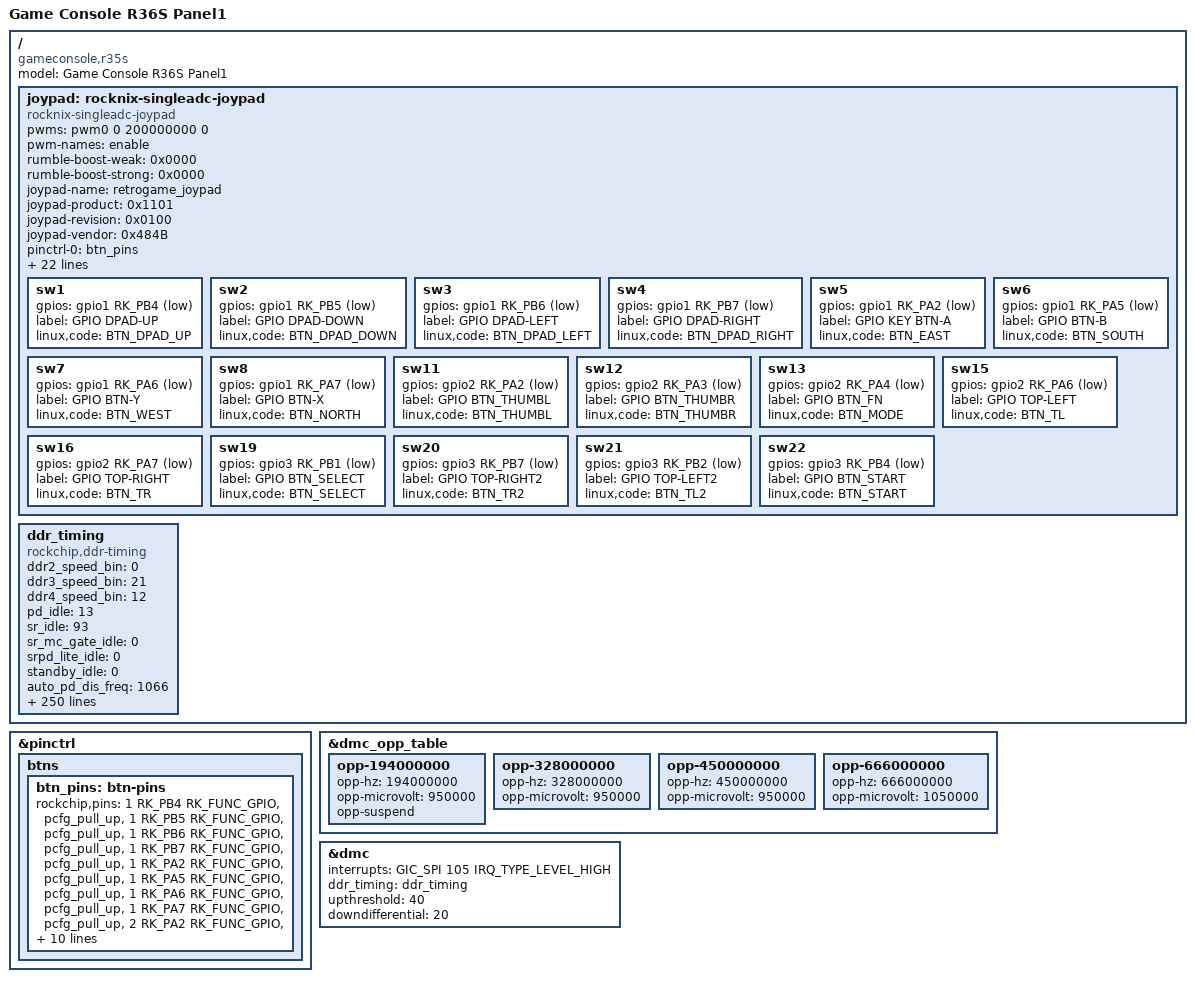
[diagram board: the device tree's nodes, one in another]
// SPDX-License-Identifier: (GPL-2.0+ OR MIT)
/*
* # Copyright (C) 2022-24 JELOS (https://github.com/JustEnoughLinuxOS)
*/

/dts-v1/;
#include "rk3326-gameconsole-r3xs.dtsi"
#include "rk3326-device-group-r36.dtsi"

/ {
	model = "Game Console R36S Panel1";
	compatible = "gameconsole,r35s", "gameconsole,r36s", "rockchip,rk3326";
	
	joypad: rocknix-singleadc-joypad {
		compatible = "rocknix-singleadc-joypad";
		pwms = <&pwm0 0 200000000 0>;
		pwm-names = "enable";
		rumble-boost-weak = <0x0000>;
		rumble-boost-strong = <0x0000>;
		
		joypad-name = "retrogame_joypad";
		joypad-product = <0x1101>;
		joypad-revision = <0x0100>;
		joypad-vendor = <0x484B>;
		
		status = "okay";
		
		/* gpio pincontrol setup */
		pinctrl-names = "default";
		pinctrl-0 = <&btn_pins>;
		pinctrl-1 = <&pwm0_pin>;
		
		/* Analog mux define */
		io-channel-names = "amux_adc";
		io-channels = <&saradc 1>;
		
		/* adc mux channel count */
		amux-count = <4>;
		/* non-default wiring */
		amux-channel-mapping = <0 1 2 3>;
		/* adc mux select(a,b) gpio */
		amux-a-gpios = <&gpio3 RK_PB3 GPIO_ACTIVE_LOW>;
		amux-b-gpios = <&gpio3 RK_PB0 GPIO_ACTIVE_LOW>;
		/* adc mux enable gpio */
		amux-en-gpios = <&gpio3 RK_PB5 GPIO_ACTIVE_LOW>;
		
		/* adc calculate scale */
		button-adc-scale = <2>;
		
		/* adc deadzone range  */
		button-adc-deadzone = <64>;
		
		/*
		specifies fuzz value that is used to filter noise from
		the event stream.
		*/
		button-adc-fuzz = <32>;
		button-adc-flat = <32>;
		
		/*
		Analog Stick data tuning value(precent)
		p = positive direction, n = negative direction
		report value = (real_adc_data * tuning_value) / 100
		*/
		abs_x-p-tuning = <200>;
		abs_x-n-tuning = <200>;
		
		abs_y-p-tuning = <200>;
		abs_y-n-tuning = <200>;
		
		abs_rx-p-tuning = <200>;
		abs_rx-n-tuning = <200>;
		
		abs_ry-p-tuning = <200>;
		abs_ry-n-tuning = <200>;
		
		/* poll device interval (ms), adc read interval */
		poll-interval = <10>;
		
		/* required for RG36S */
		invert-absx;
		invert-absy;
		
		/* gpio button auto repeat set value : default disable */
		/*
		autorepeat;
		*/
		
		/*
		joypad driver is poll-device driver.
		poll-device is does not support wakeup-source.
		*/
		sw1 {
			gpios = <&gpio1 RK_PB4 GPIO_ACTIVE_LOW>;
			label = "GPIO DPAD-UP";
			linux,code = <BTN_DPAD_UP>;// 0x220
		};
		sw2 {
			gpios = <&gpio1 RK_PB5 GPIO_ACTIVE_LOW>;
			label = "GPIO DPAD-DOWN";
			linux,code = <BTN_DPAD_DOWN>;// 0x221
		};
		sw3 {
			gpios = <&gpio1 RK_PB6 GPIO_ACTIVE_LOW>;
			label = "GPIO DPAD-LEFT";
			linux,code = <BTN_DPAD_LEFT>;// 0x222
		};
		sw4 {
			gpios = <&gpio1 RK_PB7 GPIO_ACTIVE_LOW>;
			label = "GPIO DPAD-RIGHT";
			linux,code = <BTN_DPAD_RIGHT>;// 0x223
		};
		sw5 {
			gpios = <&gpio1 RK_PA2 GPIO_ACTIVE_LOW>;
			label = "GPIO KEY BTN-A";
			linux,code = <BTN_EAST>;// 0x131
		};
		sw6 {
			gpios = <&gpio1 RK_PA5 GPIO_ACTIVE_LOW>;
			label = "GPIO BTN-B";
			linux,code = <BTN_SOUTH>;// 0x130
		};
		sw7 {
			gpios = <&gpio1 RK_PA6 GPIO_ACTIVE_LOW>;
			label = "GPIO BTN-Y";
			linux,code = <BTN_WEST>;// 0x134
		};
		sw8 {
			gpios = <&gpio1 RK_PA7 GPIO_ACTIVE_LOW>;
			label = "GPIO BTN-X";
			linux,code = <BTN_NORTH>;// 0x133
		};
		sw11 {
			gpios = <&gpio2 RK_PA2 GPIO_ACTIVE_LOW>;
			label = "GPIO BTN_THUMBL";
			linux,code = <BTN_THUMBL>;// 0x2c2
		};
		sw12 {
			gpios = <&gpio2 RK_PA3 GPIO_ACTIVE_LOW>;
			label = "GPIO BTN_THUMBR";
			linux,code = <BTN_THUMBR>;// 0x2c3
		};
		sw13 {
			gpios = <&gpio2 RK_PA4 GPIO_ACTIVE_LOW>;
			label = "GPIO BTN_FN";
			linux,code = <BTN_MODE>;// 0x2c4
		};
		sw15 {
			gpios = <&gpio2 RK_PA6 GPIO_ACTIVE_LOW>;
			label = "GPIO TOP-LEFT";
			linux,code = <BTN_TL>;// 0x02
		};
		sw16 {
			gpios = <&gpio2 RK_PA7 GPIO_ACTIVE_LOW>;
			label = "GPIO TOP-RIGHT";
			linux,code = <BTN_TR>;// 0x05
		};
		sw19 {
			gpios = <&gpio3 RK_PB1 GPIO_ACTIVE_LOW>;
			label = "GPIO BTN_SELECT";
			linux,code = <BTN_SELECT>;
		};
		sw20 {
			gpios = <&gpio3 RK_PB7 GPIO_ACTIVE_LOW>;
			label = "GPIO TOP-RIGHT2";
			linux,code = <BTN_TR2>;
		};
		sw21 {
			gpios = <&gpio3 RK_PB2 GPIO_ACTIVE_LOW>;
			label = "GPIO TOP-LEFT2";
			linux,code = <BTN_TL2>;
		};
		sw22 {
			gpios = <&gpio3 RK_PB4 GPIO_ACTIVE_LOW>;
			label = "GPIO BTN_START";
			linux,code = <BTN_START>;
		};
	};
	ddr_timing: ddr_timing {
		compatible = "rockchip,ddr-timing";
		ddr2_speed_bin = <0>;
		ddr3_speed_bin = <21>;
		ddr4_speed_bin = <12>;
		pd_idle = <13>;
		sr_idle = <93>;
		sr_mc_gate_idle = <0>;
		srpd_lite_idle = <0>;
		standby_idle = <0>;
		auto_pd_dis_freq = <1066>;
		auto_sr_dis_freq = <800>;
		ddr2_dll_dis_freq = <300>;
		ddr3_dll_dis_freq = <300>;
		ddr4_dll_dis_freq = <625>;
		phy_dll_dis_freq = <400>;
		ddr2_odt_dis_freq = <100>;
		phy_ddr2_odt_dis_freq = <100>;
		ddr2_drv = <1>;
		ddr2_odt = <150>;
		phy_ddr2_ca_drv = <21>;
		phy_ddr2_ck_drv = <18>;
		phy_ddr2_dq_drv = <21>;
		phy_ddr2_odt = <2>;
		ddr3_odt_dis_freq = <400>;
		phy_ddr3_odt_dis_freq = <400>;
		ddr3_drv = <40>;
		ddr3_odt = <120>;
		phy_ddr3_ca_drv = <21>;
		phy_ddr3_ck_drv = <18>;
		phy_ddr3_dq_drv = <21>;
		phy_ddr3_odt = <2>;
		phy_lpddr2_odt_dis_freq = <666>;
		lpddr2_drv = <40>;
		phy_lpddr2_ca_drv = <22>;
		phy_lpddr2_ck_drv = <19>;
		phy_lpddr2_dq_drv = <22>;
		phy_lpddr2_odt = <0>;
		lpddr3_odt_dis_freq = <400>;
		phy_lpddr3_odt_dis_freq = <400>;
		lpddr3_drv = <40>;
		lpddr3_odt = <240>;
		phy_lpddr3_ca_drv = <22>;
		phy_lpddr3_ck_drv = <19>;
		phy_lpddr3_dq_drv = <22>;
		phy_lpddr3_odt = <2>;
		lpddr4_odt_dis_freq = <800>;
		phy_lpddr4_odt_dis_freq = <800>;
		lpddr4_drv = <60>;
		lpddr4_dq_odt = <40>;
		lpddr4_ca_odt = <40>;
		phy_lpddr4_ca_drv = <20>;
		phy_lpddr4_ck_cs_drv = <6>;
		phy_lpddr4_dq_drv = <6>;
		phy_lpddr4_odt = <16>;
		ddr4_odt_dis_freq = <625>;
		phy_ddr4_odt_dis_freq = <625>;
		ddr4_drv = <34>;
		ddr4_odt = <240>;
		phy_ddr4_ca_drv = <22>;
		phy_ddr4_ck_drv = <19>;
		phy_ddr4_dq_drv = <22>;
		phy_ddr4_odt = <2>;
		ddr3a1_ddr4a9_de-skew = <6>;
		ddr3a0_ddr4a10_de-skew = <7>;
		ddr3a3_ddr4a6_de-skew = <7>;
		ddr3a2_ddr4a4_de-skew = <7>;
		ddr3a5_ddr4a8_de-skew = <7>;
		ddr3a4_ddr4a5_de-skew = <7>;
		ddr3a7_ddr4a11_de-skew = <7>;
		ddr3a6_ddr4a7_de-skew = <6>;
		ddr3a9_ddr4a0_de-skew = <7>;
		ddr3a8_ddr4a13_de-skew = <7>;
		ddr3a11_ddr4a3_de-skew = <7>;
		ddr3a10_ddr4cs0_de-skew = <7>;
		ddr3a13_ddr4a2_de-skew = <7>;
		ddr3a12_ddr4ba1_de-skew = <7>;
		ddr3a15_ddr4odt0_de-skew = <7>;
		ddr3a14_ddr4a1_de-skew = <7>;
		ddr3ba1_ddr4a15_de-skew = <7>;
		ddr3ba0_ddr4bg0_de-skew = <7>;
		ddr3ras_ddr4cke_de-skew = <7>;
		ddr3ba2_ddr4ba0_de-skew = <7>;
		ddr3we_ddr4bg1_de-skew = <7>;
		ddr3cas_ddr4a12_de-skew = <7>;
		ddr3ckn_ddr4ckn_de-skew = <7>;
		ddr3ckp_ddr4ckp_de-skew = <7>;
		ddr3cke_ddr4a16_de-skew = <7>;
		ddr3odt0_ddr4a14_de-skew = <7>;
		ddr3cs0_ddr4act_de-skew = <6>;
		ddr3reset_ddr4reset_de-skew = <7>;
		ddr3cs1_ddr4cs1_de-skew = <6>;
		ddr3odt1_ddr4odt1_de-skew = <7>;
		cs0_dm0_rx_de-skew = <7>;
		cs0_dm0_tx_de-skew = <7>;
		cs0_dq0_rx_de-skew = <8>;
		cs0_dq0_tx_de-skew = <8>;
		cs0_dq1_rx_de-skew = <9>;
		cs0_dq1_tx_de-skew = <8>;
		cs0_dq2_rx_de-skew = <8>;
		cs0_dq2_tx_de-skew = <8>;
		cs0_dq3_rx_de-skew = <8>;
		cs0_dq3_tx_de-skew = <8>;
		cs0_dq4_rx_de-skew = <9>;
		cs0_dq4_tx_de-skew = <8>;
		cs0_dq5_rx_de-skew = <9>;
		cs0_dq5_tx_de-skew = <8>;
		cs0_dq6_rx_de-skew = <9>;
		cs0_dq6_tx_de-skew = <8>;
		cs0_dq7_rx_de-skew = <8>;
		cs0_dq7_tx_de-skew = <8>;
		cs0_dqs0_rx_de-skew = <6>;
		cs0_dqs0p_tx_de-skew = <9>;
		cs0_dqs0n_tx_de-skew = <9>;
		cs0_dm1_rx_de-skew = <7>;
		cs0_dm1_tx_de-skew = <6>;
		cs0_dq8_rx_de-skew = <8>;
		cs0_dq8_tx_de-skew = <7>;
		cs0_dq9_rx_de-skew = <9>;
		cs0_dq9_tx_de-skew = <7>;
		cs0_dq10_rx_de-skew = <8>;
		cs0_dq10_tx_de-skew = <8>;
		cs0_dq11_rx_de-skew = <8>;
		cs0_dq11_tx_de-skew = <7>;
		cs0_dq12_rx_de-skew = <8>;
		cs0_dq12_tx_de-skew = <8>;
		cs0_dq13_rx_de-skew = <9>;
		cs0_dq13_tx_de-skew = <7>;
		cs0_dq14_rx_de-skew = <9>;
		cs0_dq14_tx_de-skew = <8>;
		cs0_dq15_rx_de-skew = <9>;
		cs0_dq15_tx_de-skew = <7>;
		cs0_dqs1_rx_de-skew = <7>;
		cs0_dqs1p_tx_de-skew = <9>;
		cs0_dqs1n_tx_de-skew = <9>;
		cs0_dm2_rx_de-skew = <7>;
		cs0_dm2_tx_de-skew = <7>;
		cs0_dq16_rx_de-skew = <9>;
		cs0_dq16_tx_de-skew = <9>;
		cs0_dq17_rx_de-skew = <7>;
		cs0_dq17_tx_de-skew = <9>;
		cs0_dq18_rx_de-skew = <7>;
		cs0_dq18_tx_de-skew = <8>;
		cs0_dq19_rx_de-skew = <7>;
		cs0_dq19_tx_de-skew = <9>;
		cs0_dq20_rx_de-skew = <9>;
		cs0_dq20_tx_de-skew = <9>;
		cs0_dq21_rx_de-skew = <9>;
		cs0_dq21_tx_de-skew = <9>;
		cs0_dq22_rx_de-skew = <8>;
		cs0_dq22_tx_de-skew = <9>;
		cs0_dq23_rx_de-skew = <8>;
		cs0_dq23_tx_de-skew = <9>;
		cs0_dqs2_rx_de-skew = <6>;
		cs0_dqs2p_tx_de-skew = <9>;
		cs0_dqs2n_tx_de-skew = <9>;
		cs0_dm3_rx_de-skew = <7>;
		cs0_dm3_tx_de-skew = <7>;
		cs0_dq24_rx_de-skew = <8>;
		cs0_dq24_tx_de-skew = <8>;
		cs0_dq25_rx_de-skew = <9>;
		cs0_dq25_tx_de-skew = <9>;
		cs0_dq26_rx_de-skew = <9>;
		cs0_dq26_tx_de-skew = <8>;
		cs0_dq27_rx_de-skew = <9>;
		cs0_dq27_tx_de-skew = <8>;
		cs0_dq28_rx_de-skew = <9>;
		cs0_dq28_tx_de-skew = <9>;
		cs0_dq29_rx_de-skew = <9>;
		cs0_dq29_tx_de-skew = <9>;
		cs0_dq30_rx_de-skew = <8>;
		cs0_dq30_tx_de-skew = <8>;
		cs0_dq31_rx_de-skew = <8>;
		cs0_dq31_tx_de-skew = <8>;
		cs0_dqs3_rx_de-skew = <7>;
		cs0_dqs3p_tx_de-skew = <9>;
		cs0_dqs3n_tx_de-skew = <9>;
		cs1_dm0_rx_de-skew = <7>;
		cs1_dm0_tx_de-skew = <7>;
		cs1_dq0_rx_de-skew = <8>;
		cs1_dq0_tx_de-skew = <8>;
		cs1_dq1_rx_de-skew = <9>;
		cs1_dq1_tx_de-skew = <8>;
		cs1_dq2_rx_de-skew = <8>;
		cs1_dq2_tx_de-skew = <8>;
		cs1_dq3_rx_de-skew = <8>;
		cs1_dq3_tx_de-skew = <8>;
		cs1_dq4_rx_de-skew = <8>;
		cs1_dq4_tx_de-skew = <8>;
		cs1_dq5_rx_de-skew = <9>;
		cs1_dq5_tx_de-skew = <8>;
		cs1_dq6_rx_de-skew = <9>;
		cs1_dq6_tx_de-skew = <8>;
		cs1_dq7_rx_de-skew = <8>;
		cs1_dq7_tx_de-skew = <8>;
		cs1_dqs0_rx_de-skew = <6>;
		cs1_dqs0p_tx_de-skew = <9>;
		cs1_dqs0n_tx_de-skew = <9>;
		cs1_dm1_rx_de-skew = <7>;
		cs1_dm1_tx_de-skew = <7>;
		cs1_dq8_rx_de-skew = <8>;
		cs1_dq8_tx_de-skew = <8>;
		cs1_dq9_rx_de-skew = <8>;
		cs1_dq9_tx_de-skew = <7>;
		cs1_dq10_rx_de-skew = <7>;
		cs1_dq10_tx_de-skew = <8>;
		cs1_dq11_rx_de-skew = <8>;
		cs1_dq11_tx_de-skew = <8>;
		cs1_dq12_rx_de-skew = <8>;
		cs1_dq12_tx_de-skew = <7>;
		cs1_dq13_rx_de-skew = <8>;
		cs1_dq13_tx_de-skew = <8>;
		cs1_dq14_rx_de-skew = <8>;
		cs1_dq14_tx_de-skew = <8>;
		cs1_dq15_rx_de-skew = <8>;
		cs1_dq15_tx_de-skew = <7>;
		cs1_dqs1_rx_de-skew = <7>;
		cs1_dqs1p_tx_de-skew = <9>;
		cs1_dqs1n_tx_de-skew = <9>;
		cs1_dm2_rx_de-skew = <7>;
		cs1_dm2_tx_de-skew = <8>;
		cs1_dq16_rx_de-skew = <8>;
		cs1_dq16_tx_de-skew = <9>;
		cs1_dq17_rx_de-skew = <8>;
		cs1_dq17_tx_de-skew = <9>;
		cs1_dq18_rx_de-skew = <7>;
		cs1_dq18_tx_de-skew = <8>;
		cs1_dq19_rx_de-skew = <8>;
		cs1_dq19_tx_de-skew = <9>;
		cs1_dq20_rx_de-skew = <9>;
		cs1_dq20_tx_de-skew = <9>;
		cs1_dq21_rx_de-skew = <9>;
		cs1_dq21_tx_de-skew = <9>;
		cs1_dq22_rx_de-skew = <8>;
		cs1_dq22_tx_de-skew = <9>;
		cs1_dq23_rx_de-skew = <8>;
		cs1_dq23_tx_de-skew = <9>;
		cs1_dqs2_rx_de-skew = <6>;
		cs1_dqs2p_tx_de-skew = <9>;
		cs1_dqs2n_tx_de-skew = <9>;
		cs1_dm3_rx_de-skew = <7>;
		cs1_dm3_tx_de-skew = <7>;
		cs1_dq24_rx_de-skew = <8>;
		cs1_dq24_tx_de-skew = <9>;
		cs1_dq25_rx_de-skew = <9>;
		cs1_dq25_tx_de-skew = <9>;
		cs1_dq26_rx_de-skew = <9>;
		cs1_dq26_tx_de-skew = <8>;
		cs1_dq27_rx_de-skew = <8>;
		cs1_dq27_tx_de-skew = <8>;
		cs1_dq28_rx_de-skew = <9>;
		cs1_dq28_tx_de-skew = <9>;
		cs1_dq29_rx_de-skew = <9>;
		cs1_dq29_tx_de-skew = <9>;
		cs1_dq30_rx_de-skew = <9>;
		cs1_dq30_tx_de-skew = <8>;
		cs1_dq31_rx_de-skew = <8>;
		cs1_dq31_tx_de-skew = <8>;
		cs1_dqs3_rx_de-skew = <7>;
		cs1_dqs3p_tx_de-skew = <9>;
		cs1_dqs3n_tx_de-skew = <9>;
	};
};

&pinctrl {
	btns {
		btn_pins: btn-pins {
			rockchip,pins = 
			<1 RK_PB4 RK_FUNC_GPIO &pcfg_pull_up>,
			<1 RK_PB5 RK_FUNC_GPIO &pcfg_pull_up>,
			<1 RK_PB6 RK_FUNC_GPIO &pcfg_pull_up>,
			<1 RK_PB7 RK_FUNC_GPIO &pcfg_pull_up>,
			<1 RK_PA2 RK_FUNC_GPIO &pcfg_pull_up>,
			<1 RK_PA5 RK_FUNC_GPIO &pcfg_pull_up>,
			<1 RK_PA6 RK_FUNC_GPIO &pcfg_pull_up>,
			<1 RK_PA7 RK_FUNC_GPIO &pcfg_pull_up>,
			<2 RK_PA2 RK_FUNC_GPIO &pcfg_pull_up>,
			<2 RK_PA3 RK_FUNC_GPIO &pcfg_pull_up>,
			<2 RK_PA4 RK_FUNC_GPIO &pcfg_pull_up>,
			<2 RK_PA5 RK_FUNC_GPIO &pcfg_pull_up>,
			<2 RK_PA6 RK_FUNC_GPIO &pcfg_pull_up>,
			<2 RK_PA7 RK_FUNC_GPIO &pcfg_pull_up>,
			<3 RK_PB1 RK_FUNC_GPIO &pcfg_pull_up>,
			<3 RK_PB2 RK_FUNC_GPIO &pcfg_pull_up>,
			<3 RK_PB4 RK_FUNC_GPIO &pcfg_pull_up>,
			<3 RK_PB7 RK_FUNC_GPIO &pcfg_pull_up>;
		};
	};
};

&dmc_opp_table {
	/delete-node/ opp-924000000;
	opp-194000000 {
		opp-hz = /bits/ 64 <194000000>;
		opp-microvolt = <950000>;
		opp-suspend;
	};
	opp-328000000 {
		opp-hz = /bits/ 64 <328000000>;
		opp-microvolt = <950000>;
	};
	opp-450000000 {
		opp-hz = /bits/ 64 <450000000>;
		opp-microvolt = <950000>;
	};
	opp-666000000 {
		opp-hz = /bits/ 64 <666000000>;
		opp-microvolt = <1050000>;
	};
};

&dmc {
	interrupts = <GIC_SPI 105 IRQ_TYPE_LEVEL_HIGH>;
	interrupt-names = "complete_irq";
	ddr_timing = <&ddr_timing>;
	upthreshold = <40>;
	downdifferential = <20>;
};
